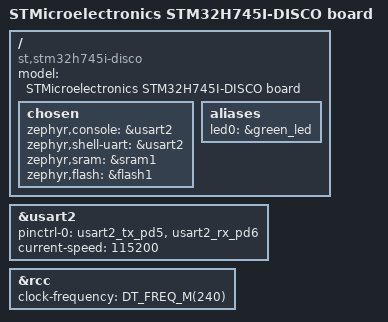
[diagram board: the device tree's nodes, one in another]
/*
 * Copyright (c) 2020 Alexander Kozhinov <AlexanderKozhinov@yandex.com>
 * Copyright (c) 2024 Tomas Jurena <jurena@utb.cz>
 *
 * SPDX-License-Identifier: Apache-2.0
 */

/dts-v1/;
#include <st/h7/stm32h745Xi_m4.dtsi>
#include "stm32h745i_disco.dtsi"

/ {
	model = "STMicroelectronics STM32H745I-DISCO board";
	compatible = "st,stm32h745i-disco";

	/* HW resources belonging to CM4 */
	chosen {
		zephyr,console = &usart2;
		zephyr,shell-uart = &usart2;
		zephyr,sram = &sram1;
		zephyr,flash = &flash1;
	};

	aliases {
		led0 = &green_led;
	};
};

&usart2 {
	pinctrl-0 = <&usart2_tx_pd5 &usart2_rx_pd6>;
	pinctrl-names = "default";
	current-speed = <115200>;
	status = "okay";
};

&rcc {
	clock-frequency = <DT_FREQ_M(240)>;
};
